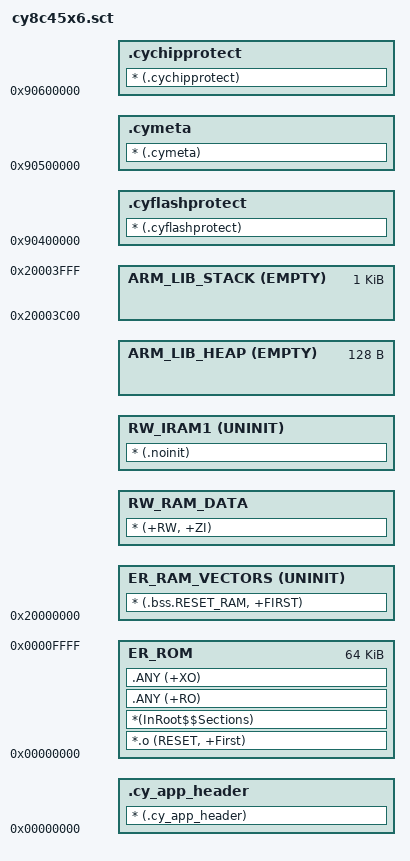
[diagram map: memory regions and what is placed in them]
#! armclang -E --target=arm-arm-none-eabi -x c -mcpu=cortex-m0
; The first line specifies a preprocessor command that the linker invokes
; to pass a scatter file through a C preprocessor.

;*******************************************************************************
;* \file cy8c45x6.sct
;* \version 1.0
;*
;* Linker file for the ARMCC.
;*
;* The main purpose of the linker script is to describe how the sections in the
;* input files should be mapped into the output file, and to control the memory
;* layout of the output file.
;*
;* \note The entry point location is fixed and starts at 0x00000000. The valid
;* application image should be placed there.
;*
;* \note The linker files included with the PDL template projects must be
;* generic and handle all common use cases. Your project may not use every
;* section defined in the linker files. In that case you may see the warnings
;* during the build process: L6314W (no section matches pattern) and/or L6329W
;* (pattern only matches removed unused sections). In your project, you can
;* suppress the warning by passing the "--diag_suppress=L6314W,L6329W" option to
;* the linker, simply comment out or remove the relevant code in the linker
;* file.
;*
;*******************************************************************************
;* \copyright
;* Copyright 2019-2020 Cypress Semiconductor Corporation
;* SPDX-License-Identifier: Apache-2.0
;*
;* Licensed under the Apache License, Version 2.0 (the "License");
;* you may not use this file except in compliance with the License.
;* You may obtain a copy of the License at
;*
;*     http://www.apache.org/licenses/LICENSE-2.0
;*
;* Unless required by applicable law or agreed to in writing, software
;* distributed under the License is distributed on an "AS IS" BASIS,
;* WITHOUT WARRANTIES OR CONDITIONS OF ANY KIND, either express or implied.
;* See the License for the specific language governing permissions and
;* limitations under the License.
;******************************************************************************/

; The defines below describe the location and size of blocks of memory in the target.
; Use these defines to specify the memory regions available for allocation.

; The following defines control RAM and flash memory allocation.
; You can change the memory allocation by editing the RAM and Flash defines.

/*--------------------- Embedded RAM Configuration ---------------------------
; <h> RAM Configuration
;   <o0> RAM Base Address    <0x0-0xFFFFFFFF:8>
;   <o1> RAM Size (in Bytes) <0x0-0xFFFFFFFF:8>
; </h>
 *----------------------------------------------------------------------------*/
#define __RAM_START    0x20000000
#define __RAM_SIZE     0x00004000

/*--------------------- Flash Configuration ----------------------------------
; <h> Flash Configuration
;   <o0> Flash Base Address <0x0-0xFFFFFFFF:8>
;   <o1> Flash Size (in Bytes) <0x0-0xFFFFFFFF:8>
; </h>
 *----------------------------------------------------------------------------*/
#define __FLASH_START  0x00000000
#define __FLASH_SIZE   0x00010000

/*--------------------- Stack / Heap Configuration ---------------------------
; <h> Stack / Heap Configuration
;   <o0> Stack Size (in Bytes) <0x0-0xFFFFFFFF:8>
;   <o1> Heap Size (in Bytes) <0x0-0xFFFFFFFF:8>
; </h>
 *----------------------------------------------------------------------------*/
#define __STACK_SIZE       0x00000400
#define __HEAP_SIZE        0x00000080


/*----------------------------------------------------------------------------
  User Stack & Heap boundery definition
 *----------------------------------------------------------------------------*/
#define __STACK_TOP        (__RAM_START + __RAM_SIZE)      /* starts at end of RAM */
#define __HEAP_BASE        (AlignExpr(+0, 8))              /* starts after RW_RAM section, 8 byte aligned */


/*----------------------------------------------------------------------------
  Scatter File Definitions definition
 *----------------------------------------------------------------------------*/
#define __RO_BASE         __FLASH_START
#define __RO_SIZE         __FLASH_SIZE

#define __RW_BASE        (__RAM_START        )
#define __RW_SIZE        (__RAM_SIZE - __STACK_SIZE - __HEAP_SIZE)


LR_ROM __RO_BASE __RO_SIZE  {                       ; load region size_region

    .cy_app_header +0
    {
        * (.cy_app_header)
    }
    
    ER_ROM __RO_BASE __RO_SIZE  {                     ; load address = execution address
        *.o (RESET, +First)
        *(InRoot$$Sections)
        .ANY (+RO)
        .ANY (+XO)
    }

    ER_RAM_VECTORS __RAM_START UNINIT
    {
        * (.bss.RESET_RAM, +FIRST)
    }

    RW_RAM_DATA +0
    {
        * (+RW, +ZI)
    }

    ; Place variables in the section that should not be initialized during the
    ; device startup.
    RW_IRAM1 +0 UNINIT
    {
        * (.noinit)
    }
#if __HEAP_SIZE > 0
    ARM_LIB_HEAP  __HEAP_BASE EMPTY  __HEAP_SIZE  {   ; Reserve empty region for heap
    }
#endif

    ARM_LIB_STACK __STACK_TOP EMPTY -__STACK_SIZE {   ; Reserve empty region for stack
    }
}


; These sections are used for additional metadata (silicon revision, Silicon/JTAG ID, etc.) storage.
CYFLASHPROTECT 0x90400000
{
    .cyflashprotect +0 { * (.cyflashprotect) }
}

CYMETA 0x90500000
{
    .cymeta +0 { * (.cymeta) }
}

CYCHIPPROTECT 0x90600000
{
    .cychipprotect +0 { * (.cychipprotect) }
}

/* The following symbols used by the cymcuelftool. */
/* Flash */
#define __cy_memory_0_start 0x00000000
#define __cy_memory_0_length  0x00010000
#define __cy_memory_0_row_size 0x200


/* [] END OF FILE */
